VERSION ""

NS_ :

BS_:

BU_: BRIDGE MASTER GEO MOTOR SENSOR

BO_ 768 GEO_HEARTBEAT: 1 GEO
 SG_ GEO_HEARTBEAT_cmd : 0|8@1+ (1,0) [0|0] "" MASTER

BO_ 256 SENSOR_HEARTBEAT: 1 SENSOR
 SG_ SENSOR_HEARTBEAT_cmd : 0|8@1+ (1,0) [0|0] "" MASTER

BO_ 1024 BRIDGE_HEARTBEAT: 1 BRIDGE
 SG_ BRIDGE_HEARTBEAT_cmd : 0|8@1+ (1,0) [0|0] "" MASTER

BO_ 512 MOTOR_HEARTBEAT: 1 MOTOR
 SG_ MOTOR_HEARTBEAT_cmd : 0|8@1+ (1,0) [0|0] "" MASTER

BO_ 0 MASTER_HEARTBEAT: 1 MASTER
 SG_ MASTER_HEARTBEAT_cmd : 0|8@1+ (1,0) [0|0] "" MOTOR

BO_ 769 GEO_DATA: 8 GEO
 SG_ GEO_DATA_Distance : 0|32@1+ (0.01,0) [0|0] "" MASTER
 SG_ GEO_DATA_Angle : 32|32@1+ (0.1,-180) [0|0] "" MASTER

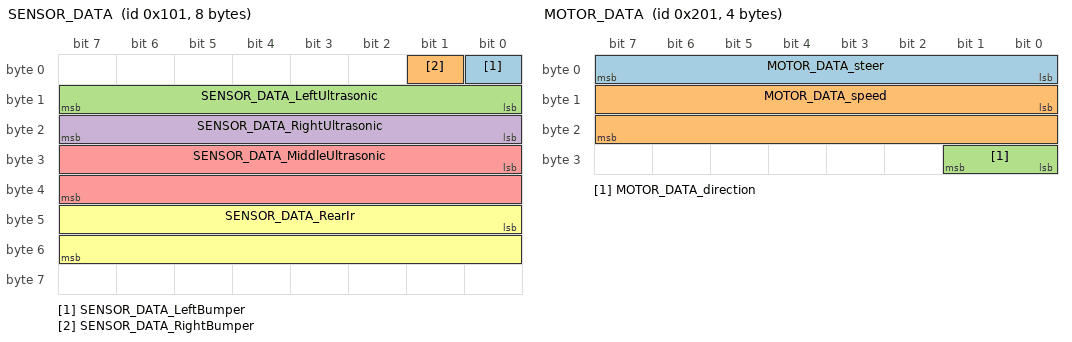
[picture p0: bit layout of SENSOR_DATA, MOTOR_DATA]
BO_ 257 SENSOR_DATA: 8 SENSOR
 SG_ SENSOR_DATA_LeftBumper : 0|1@1+ (1,0) [0|0] "" MASTER
 SG_ SENSOR_DATA_RightBumper : 1|1@1+ (1,0) [0|0] "" MASTER
 SG_ SENSOR_DATA_LeftUltrasonic : 8|8@1+ (1,0) [0|0] "" MASTER
 SG_ SENSOR_DATA_RightUltrasonic : 16|8@1+ (1,0) [0|0] "" MASTER
 SG_ SENSOR_DATA_MiddleUltrasonic : 24|16@1+ (1,0) [0|0] "" MASTER
 SG_ SENSOR_DATA_RearIr : 40|16@1+ (1,0) [0|0] "" MASTER

BO_ 1025 BRIDGE_DATA: 1 BRIDGE
 SG_ BRIDGE_DATA_cmd : 0|8@1+ (1,0) [0|0] "" MASTER

BO_ 513 MOTOR_DATA: 4 MOTOR
 SG_ MOTOR_DATA_steer : 0|8@1- (1,0) [0|0] "" MASTER,BRIDGE
 SG_ MOTOR_DATA_speed : 8|16@1+ (0.1,0) [0|0] "MPS" MASTER,BRIDGE
 SG_ MOTOR_DATA_direction : 24|2@1+ (1,0) [0|0] "" MASTER,BRIDGE

BO_ 514 MOTOR_DEBUG: 8 MOTOR
 SG_ MOTOR_DEBUG_mux M : 0|8@1+ (1,0) [0|0] "" MASTER,BRIDGE,DEBUG
 SG_ MOTOR_DEBUG_rpm_partial m0 : 8|8@1- (1,0) [0|0] "rpm" MASTER,BRIDGE,DEBUG
 SG_ MOTOR_DEBUG_rpm_actual m0 : 16|32@1- (0.001,0) [0|0] "rpm" MASTER,BRIDGE,DEBUG
 SG_ MOTOR_DEBUG_pi_error m1 : 8|32@1- (0.001,0) [0|0] "mps" MASTER,BRIDGE,DEBUG
 SG_ MOTOR_DEBUG_large_error_cnt m1 : 41|8@1+ (1,0) [0|0] "" MASTER,BRIDGE,DEBUG
 SG_ MOTOR_DEBUG_prop_cmd m2 : 8|32@1- (0.001,0) [0|0] "" MASTER,BRIDGE,DEBUG
 SG_ MOTOR_DEBUG_int_cmd m3 : 8|32@1- (0.001,0) [0|0] "" MASTER,BRIDGE,DEBUG
 SG_ MOTOR_DEBUG_int_cmd_old m4 : 8|32@1- (0.001,0) [0|0] "" MASTER,BRIDGE,DEBUG
 SG_ MOTOR_DEBUG_output m5 : 8|32@1- (0.001,0) [0|0] "percent" MASTER,BRIDGE,DEBUG
 SG_ MOTOR_DEBUG_pwm_act m6 : 8|32@1- (0.001,0) [0|0] "pwm pulse width" MASTER,BRIDGE,DEBUG

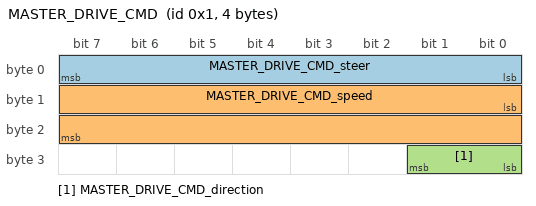
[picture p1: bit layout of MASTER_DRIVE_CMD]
BO_ 1 MASTER_DRIVE_CMD: 4 MASTER
 SG_ MASTER_DRIVE_CMD_steer : 0|8@1- (1,0) [0|0] "" MOTOR
 SG_ MASTER_DRIVE_CMD_speed : 8|16@1+ (0.1,0) [0|0] "MPS" MOTOR
 SG_ MASTER_DRIVE_CMD_direction : 24|2@1+ (1,0) [0|0] "" MOTOR

BA_ "FieldType" SG_ 1 MASTER_DRIVE_CMD_direction "MASTER_DRIVE_CMD_direction_E";
BA_ "FieldType" SG_ 513 MOTOR_DATA_direction "MOTOR_DATA_direction_E";

VAL_ 1 MASTER_DRIVE_CMD_direction 0 "stop_cmd" 1 "forward_cmd" 2 "backward_cmd" ;
VAL_ 513 MOTOR_DATA_direction 0 "stop_act" 1 "forward_act" 2 "backward_act" ;

BA_DEF_ "BusType" STRING ;
BA_DEF_ SG_ "FieldType" STRING ;

BA_DEF_DEF_ "BusType" "CAN";
BA_DEF_DEF_ "FieldType" "";
